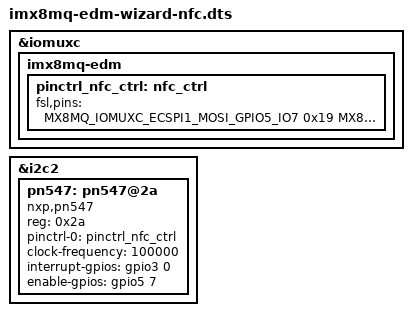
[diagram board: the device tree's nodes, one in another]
/*
 * Copyright 2018 Technexion Ltd.
 * Copyright 2017 NXP
 *
 * Author: Hank Chang <hank.chang@technexion.com>
 *
 * This program is free software; you can redistribute it and/or
 * modify it under the terms of the GNU General Public License
 * as published by the Free Software Foundation; either version 2
 * of the License, or (at your option) any later version.
 *
 * This program is distributed in the hope that it will be useful,
 * but WITHOUT ANY WARRANTY; without even the implied warranty of
 * MERCHANTABILITY or FITNESS FOR A PARTICULAR PURPOSE.  See the
 * GNU General Public License for more details.
 */

#include "imx8mq-edm-wizard.dts"

&iomuxc {
	imx8mq-edm {
		pinctrl_nfc_ctrl: nfc_ctrl {
			fsl,pins = <
				MX8MQ_IOMUXC_ECSPI1_MOSI_GPIO5_IO7		0x19	/* PIN_ENABLE */
				MX8MQ_IOMUXC_NAND_ALE_GPIO3_IO0			0x19	/* PIN_INT */
			>;
		};
	};
};

&i2c2 {
	status = "okay";

	pn547: pn547@2a {
		compatible = "nxp,pn547";
		reg = <0x2a>;
		pinctrl-names = "default";
		pinctrl-0 = <&pinctrl_nfc_ctrl>;
		clock-frequency = <100000>;
		interrupt-gpios = <&gpio3 0 0>;
		enable-gpios = <&gpio5 7 0>;
		status = "okay";
	};
};
